# CC2753 register map
File version: 1.0
CPU: CM0+ r0p4, little endian, no MPU, no FPU, VTOR, 3 interrupt priority bits
Registers are 32-bit, read-write, reset 0x0 unless marked. A register's access mark holds for its fields unless they carry their own. Offsets are from the block's base; [hi:lo] are bit positions; 'fields as' and 'values as' point back to an identical list.

## CKMD (part 1 of 2) — Clock Controller
Base 0x40001000
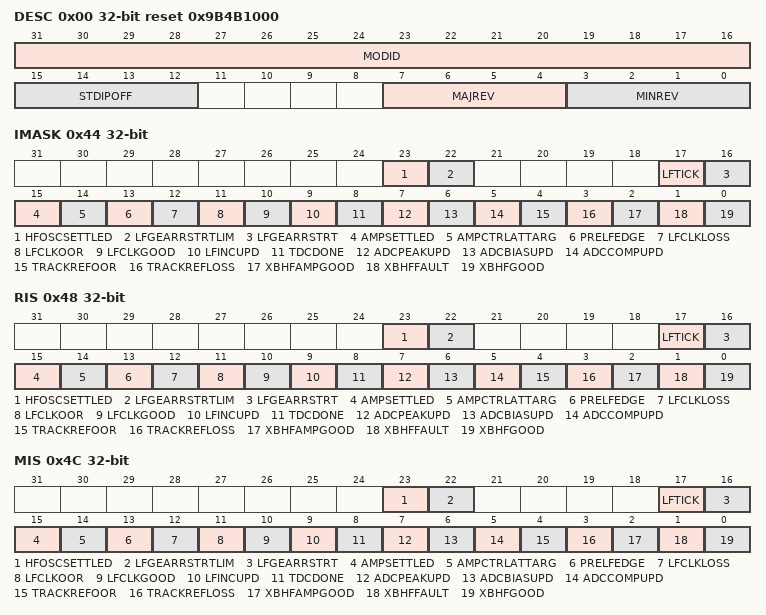
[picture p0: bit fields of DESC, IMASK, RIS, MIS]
0x00 DESC ro reset 0x9B4B1000 — Description Register. This register provides IP module ID, revision information, instance index and standard MMR registers offset.
  [31:16] MODID — Module identifier used to uniquely identify this IP.
  [15:12] STDIPOFF — Standard IP MMR block offset. Standard IP MMRs are the set of from aggregated IRQ registers till DTB. 0: Standard IP MMRs do not exist 0x1-0xF: Standard IP MMRs begin at offset of (64*STDIPOFF from the base IP address) NOTE: This IP does not have DTB as part of the Standard IP MMRs. It uses DTBCTL instead.
  [7:4] MAJREV — Major revision of IP (0-15).
  [3:0] MINREV — Minor revision of IP (0-15).
0x44 IMASK — Interrupt mask register
  [23] HFOSCSETTLED — Indicates that HFOSC has settled, based on LOOPCFG.SETTLED_TARGET and LOOPCFG1.SETTLEIRQ
  [22] LFGEARRSTRTLIM — Indicates that the LFINC filter gearing mechanism has restarted more than LFINCCTL2.GEARRSTRTLIM
  [17] LFTICK — 32kHz TICK to RTC and WDT. Either derived from selected LFCLK or generated from CLKULL in absence of LFCLK.
  [16] LFGEARRSTRT — LFINC filter gearing restart. Indicates that the LFINC filter restarted gearing. Subsequent LFINC estimates may have higher variation.
  [15] AMPSETTLED — HFXT Amplitude compensation - settled Indicates that the amplitude compensation FSM has reached the SETTLED or TCXOMODE state, and the controls configured in HFXTTARG or HFXTDYN are reached.
  [14] AMPCTRLATTARG — HFXT Amplitude compensation - controls at target Indicates that the control values configured in HFXTTARG or HFXTDYN are reached. Applies to Q1CAP, Q2CAP and IREF.
  [13] PRELFEDGE — Pre-LF clock edge detect. Indicates that a positive edge occured on the selected pre-LF clock CLKSEL.PRELFCLK' Can be used by software to confirm that a LF clock source is running and within the expected frequency, before selecting it as the main LF clock source.
  [12] LFCLKLOSS — LF clock is lost. Indicates that no LF clock edge occured for ~49us (~1.6 times nominal period). The system will automatically fall-back to generating LFTICK based on CLKULL, to avoid timing corruption. Note that this signal is NOT related to the analog LF clock-loss detector which can reset the device during STANDBY.
  [11] LFCLKOOR — LF clock period out-of-range. Indicates that a LF clock period was measured to be out-of-range, according to LFQUALCTL.MAXERR.
  [10] LFCLKGOOD — LF clock good. Indicates that the LF clock is good, according to the configuration in LFQUALCTL.
  [9] LFINCUPD — LFINC updated. Indicates that a new LFINC measurement value is available in CKM.LFCLKSTAT.
  [8] TDCDONE — TDC done event. Indicates that the TDC measurement is done.
  [7] ADCPEAKUPD — HFXT-ADC PEAK measurement update event. Indicates that the HFXT-ADC PEAK measurement is done.
  [6] ADCBIASUPD — HFXT-ADC BIAS measurement update event. Indicates that the HFXT-ADC BIAS measurement is done.
  [5] ADCCOMPUPD — HFXT-ADC comparison update event. Indicates that the HFXT-ADC comparison is done.
  [4] TRACKREFOOR — Out-of-range indication from the tracking loop. Indicates that the selected reference clock frequency of the tracking loop is out-of-range.
  [3] TRACKREFLOSS — Clock loss indication from the tracking loop. Indicates that the selected reference clock of the tracking loop is lost.
  [2] XBHFAMPGOOD — For HFXT it indicates that the amplitude is good. For BAW it indicates that the 1st stage qualification is done.
  [1] XBHFFAULT — HFXT/BAW fault indication. Indicates that HFXT/BAW did not start correctly, or its frequency is too low. HFXT/BAW will not recover from this fault and has to be restarted. This is only a one-time check at HFXT/BAW startup.
  [0] XBHFGOOD — HFXT/BAW good indication. Indicates that HFXT/BAW started correctly. The frequency is not necessarily good enough for radio operation. This is only a one-time check at HFXT/BAW startup.
0x48 RIS ro — Raw interrupt flag register
  [23] HFOSCSETTLED — Indicates that HFOSC has settled, based on LOOPCFG.SETTLED_TARGET and LOOPCFG1.SETTLEIRQ
  [22] LFGEARRSTRTLIM — Indicates that the LFINC filter gearing mechanism has restarted more than LFINCCTL2.GEARRSTRTLIM
  [17] LFTICK — 32kHz TICK to RTC and WDT. Either derived from selected LFCLK or generated from CLKULL in absence of LFCLK.
  [16] LFGEARRSTRT — LFINC filter gearing restart. Indicates that the LFINC filter restarted gearing. Subsequent LFINC estimates may have higher variation.
  [15] AMPSETTLED — HFXT Amplitude compensation - settled Indicates that the amplitude compensation FSM has reached the SETTLED or TCXOMODE state, and the controls configured in HFXTTARG or HFXTDYN are reached.
  [14] AMPCTRLATTARG — HFXT Amplitude compensation - controls at target Indicates that the control values configured in HFXTTARG or HFXTDYN are reached. Applies to Q1CAP, Q2CAP and IREF.
  [13] PRELFEDGE — Pre-LF clock edge detect. Indicates that a positive edge occured on the selected pre-LF clock CLKSEL.PRELFCLK' Can be used by software to confirm that a LF clock source is running and within the expected frequency, before selecting it as the main LF clock source.
  [12] LFCLKLOSS — LF clock is lost. Indicates that no LF clock edge occured for ~49us (~1.6 times nominal period). The system will automatically fall-back to generating LFTICK based on CLKULL, to avoid timing corruption. Note that this signal is NOT related to the analog LF clock-loss detector which can reset the device during STANDBY.
  [11] LFCLKOOR — LF clock period out-of-range. Indicates that a LF clock period was measured to be out-of-range, according to LFQUALCTL.MAXERR.
  [10] LFCLKGOOD — LF clock good. Indicates that the LF clock is good, according to the configuration in LFQUALCTL.
  [9] LFINCUPD — LFINC updated. Indicates that a new LFINC measurement value is available in CKM.LFCLKSTAT.
  [8] TDCDONE — TDC done event. Indicates that the TDC measurement is done.
  [7] ADCPEAKUPD — HFXT-ADC PEAK measurement update event. Indicates that the HFXT-ADC PEAK measurement is done.
  [6] ADCBIASUPD — HFXT-ADC BIAS measurement update event. Indicates that the HFXT-ADC BIAS measurement is done.
  [5] ADCCOMPUPD — HFXT-ADC comparison update event. Indicates that the HFXT-ADC comparison is done.
  [4] TRACKREFOOR — Out-of-range indication from the tracking loop. Indicates that the selected reference clock frequency of the tracking loop is out-of-range. Configured using the MMR LOOPCFG.OOR_LIMIT
  [3] TRACKREFLOSS — Clock loss indication from the tracking loop. Indicates that the selected reference clock of the tracking loop is lost.
  [2] XBHFAMPGOOD — For HFXT it indicates that the amplitude is good. For BAW it indicates that the 1st stage qualification is done.
  [1] XBHFFAULT — HFXT/BAW fault indication. Indicates that HFXT/BAW did not start correctly, or its frequency is too low. HFXT/BAW will not recover from this fault and has to be restarted. This is only a one-time check at HFXT/BAW startup.
  [0] XBHFGOOD — HFXT/BAW good indication. Indicates that HFXT/BAW started correctly. For HFXT, the frequency is not necessarily good enough for radio operation. For BAW, the frequency is good enough for radio operation. This is only a one-time check at HFXT/BAW startup.
0x4C MIS ro — Masked interrupt flag register
  [23] HFOSCSETTLED — Indicates that HFOSC has settled, based on LOOPCFG.SETTLED_TARGET and LOOPCFG1.SETTLEIRQ
  [22] LFGEARRSTRTLIM — Indicates that the LFINC filter gearing mechanism has restarted more than LFINCCTL2.GEARRSTRTLIM
  [17] LFTICK — 32kHz TICK to RTC and WDT. Either derived from selected LFCLK or generated from CLKULL in absence of LFCLK.
  [16] LFGEARRSTRT — LFINC filter gearing restart. Indicates that the LFINC filter restarted gearing. Subsequent LFINC estimates may have higher variation.
  [15] AMPSETTLED — HFXT Amplitude compensation - settled Indicates that the amplitude compensation FSM has reached the SETTLED or TCXOMODE state, and the controls configured in HFXTTARG or HFXTDYN are reached.
  [14] AMPCTRLATTARG — HFXT Amplitude compensation - controls at target Indicates that the control values configured in HFXTTARG or HFXTDYN are reached. Applies to Q1CAP, Q2CAP and IREF.
  [13] PRELFEDGE — Pre-LF clock edge detect. Indicates that a positive edge occured on the selected pre-LF clock CLKSEL.PRELFCLK' Can be used by software to confirm that a LF clock source is running and within the expected frequency, before selecting it as the main LF clock source.
  [12] LFCLKLOSS — LF clock is lost. Indicates that no LF clock edge occured for ~49us (~1.6 times nominal period). The system will automatically fall-back to generating LFTICK based on CLKULL, to avoid timing corruption. Note that this signal is NOT related to the analog LF clock-loss detector which can reset the device during STANDBY.
  [11] LFCLKOOR — LF clock period out-of-range. Indicates that a LF clock period was measured to be out-of-range, according to LFQUALCTL.MAXERR.
  [10] LFCLKGOOD — LF clock good. Indicates that the LF clock is good, according to the configuration in LFQUALCTL.
  [9] LFINCUPD — LFINC updated. Indicates that a new LFINC measurement value is available in CKM.LFCLKSTAT.
  [8] TDCDONE — TDC done event. Indicates that the TDC measurement is done.
  [7] ADCPEAKUPD — HFXT-ADC PEAK measurement update event. Indicates that the HFXT-ADC PEAK measurement is done.
  [6] ADCBIASUPD — HFXT-ADC BIAS measurement update event. Indicates that the HFXT-ADC BIAS measurement is done.
  [5] ADCCOMPUPD — HFXT-ADC comparison update event. Indicates that the HFXT-ADC comparison is done.
  [4] TRACKREFOOR — Out-of-range indication from the tracking loop. Indicates that the selected reference clock frequency of the tracking loop is out-of-range.
  [3] TRACKREFLOSS — Clock loss indication from the tracking loop. Indicates that the selected reference clock of the tracking loop is lost.
  [2] XBHFAMPGOOD — For HFXT it indicates that the amplitude is good. For BAW it indicates that the 1st stage qualification is done.
  [1] XBHFFAULT — HFXT/BAW fault indication. Indicates that HFXT/BAW did not start correctly, or its frequency is too low. HFXT/BAW will not recover from this fault and has to be restarted. This is only a one-time check at HFXT/BAW startup.
  [0] XBHFGOOD — HFXT/BAW good indication. Indicates that HFXT/BAW started correctly. For HFXT, the frequency is not necessarily good enough for radio operation. For BAW, the frequency is good enough for radio operation. This is only a one-time check at HFXT/BAW startup.
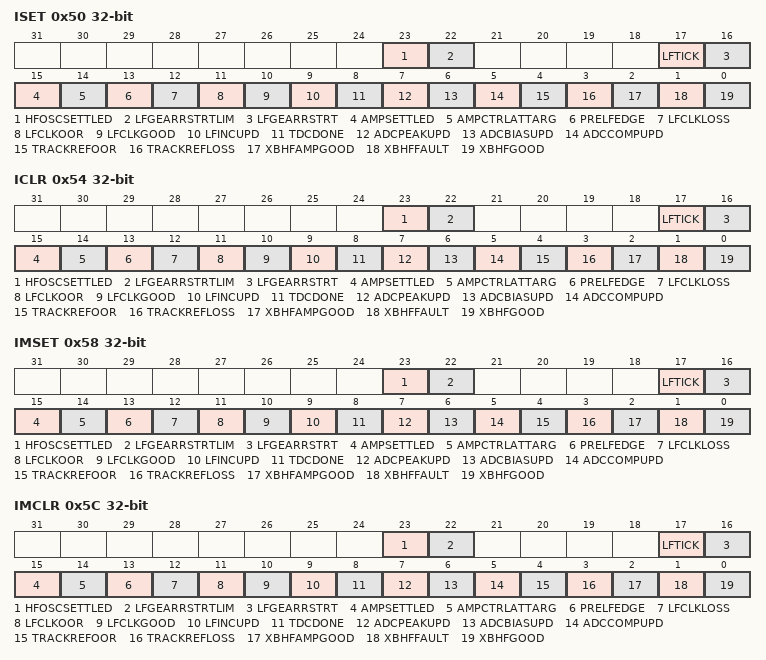
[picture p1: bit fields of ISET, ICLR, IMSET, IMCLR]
0x50 ISET wo — Interrupt flag set register
  fields as MIS
0x54 ICLR wo — Interrupt flag clear register
  fields as MIS
0x58 IMSET wo — Interrupt mask set register
  [23] HFOSCSETTLED — Indicates that HFOSC has settled, based on LOOPCFG.SETTLED_TARGET and LOOPCFG1.SETTLEIRQ
  [22] LFGEARRSTRTLIM — Indicates that the LFINC filter gearing mechanism has restarted more than LFINCCTL2.GEARRSTRTLIM
  [17] LFTICK — 32kHz TICK to RTC and WDT. Either derived from selected LFCLK or generated from CLKULL in absence of LFCLK.
  [16] LFGEARRSTRT — LFINC filter gearing restart. Indicates that the LFINC filter restarted gearing. Subsequent LFINC estimates may have higher variation.
  [15] AMPSETTLED — HFXT Amplitude compensation - settled Indicates that the amplitude compensation FSM has reached the SETTLED or TCXOMODE state, and the controls configured in HFXTTARG or HFXTDYN are reached.
  [14] AMPCTRLATTARG — HFXT Amplitude compensation - controls at target Indicates that the control values configured in HFXTTARG or HFXTDYN are reached. Applies to Q1CAP, Q2CAP and IREF.
  [13] PRELFEDGE — Pre-LF clock edge detect. Indicates that a positive edge occured on the selected pre-LF clock CLKSEL.PRELFCLK' Can be used by software to confirm that a LF clock source is running and within the expected frequency, before selecting it as the main LF clock source.
  [12] LFCLKLOSS — LF clock is lost. Indicates that no LF clock edge occured for ~49us (~1.6 times nominal period). The system will automatically fall-back to generating LFTICK based on CLKULL, to avoid timing corruption. Note that this signal is NOT related to the analog LF clock-loss detector which can reset the device during STANDBY.
  [11] LFCLKOOR — LF clock period out-of-range. Indicates that a LF clock period was measured to be out-of-range, according to LFQUALCTL.MAXERR.
  [10] LFCLKGOOD — LF clock good. Indicates that the LF clock is good, according to the configuration in LFQUALCTL.
  [9] LFINCUPD — LFINC updated. Indicates that a new LFINC measurement value is available in CKM.LFCLKSTAT.
  [8] TDCDONE — TDC done event. Indicates that the TDC measurement is done.
  [7] ADCPEAKUPD — HFXT-ADC PEAK measurement update event. Indicates that the HFXT-ADC PEAK measurement is done.
  [6] ADCBIASUPD — HFXT-ADC BIAS measurement update event. Indicates that the HFXT-ADC BIAS measurement is done.
  [5] ADCCOMPUPD — HFXT-ADC comparison update event. Indicates that the HFXT-ADC comparison is done.
  [4] TRACKREFOOR — Out-of-range indication from the tracking loop. Indicates that the selected reference clock frequency of the tracking loop is out-of-range.
  [3] TRACKREFLOSS — Clock loss indication from the tracking loop. Indicates that the selected reference clock of the tracking loop is lost.
  [2] XBHFAMPGOOD — HFXT amplitude good indication.
  [1] XBHFFAULT — HFXT/BAW fault indication. Indicates that HFXT/BAW did not start correctly, or its frequency is too low. HFXT/BAW will not recover from this fault and has to be restarted. This is only a one-time check at HFXT/BAW startup.
  [0] XBHFGOOD — HFXT/BAW good indication. Indicates that HFXT/BAW started correctly. For HFXT, the frequency is not necessarily good enough for radio operation. For BAW, the frequency is good enough for radio operation. This is only a one-time check at HFXT/BAW startup.
0x5C IMCLR wo — Indicates that HFOSC has settled, based on LOOPCFG.SETTLED_TARGET
  fields as MIS
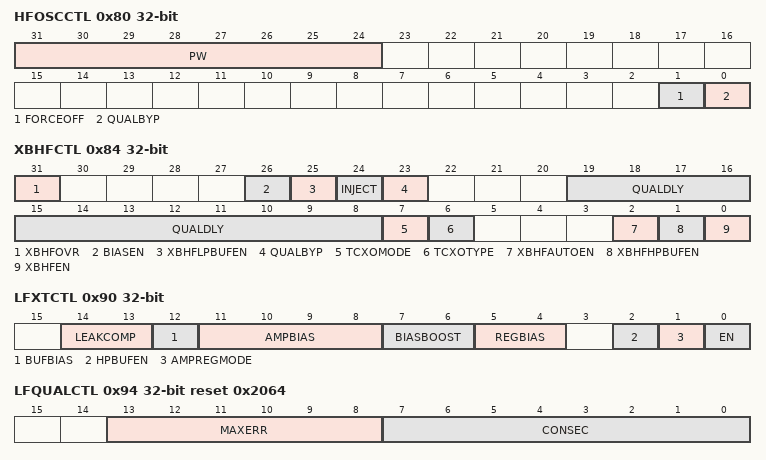
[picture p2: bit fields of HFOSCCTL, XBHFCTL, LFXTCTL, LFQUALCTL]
0x80 HFOSCCTL — High frequency oscillator control
  [31:24] PW wo — Password protection for QUALBYP and FORCEOFF. Write this field to 0xA5 to accept writes to QUALBYP and FORCEOFF.
  [1] FORCEOFF — Force HFOSC off. Once this MMR is set, the system will stop. The only way to start the system again is system reset. This field is locked using the global-lock within SYS0.
  [0] QUALBYP — Clock qualification bypass. HFOSC qualification will skip a fixed number of clock cycles to prevent glitches or frequency overshoots from reaching the system. Setting this bit will bypass the qualification. This bit can be locked in SYS0. If unlocked, it is password protected with PW.
0x84 XBHFCTL — High frequency crystal controls
  [31] XBHFOVR — Software override for the HFXT amplitude compensation FSM or BAW control FSM HFXT overrides :- Directly use control values in CKM.HFXTDYN0 and CKM.HFXTDYN1. Control injection and clock buffer using INJECT and LPBUFEN. BAW overrides :- Directly use control values in CKM.BAWCTL
  [26] BIASEN — HFXT bias enable. Controls the biasing if XBHFOVR is set. Otherwise, the biasing is controlled by the amplitude compensation FSM.
  [25] XBHFLPBUFEN — Low power clock buffer enable. Controls the clock buffer if XBHFOVR is set. Otherwise, the buffer is controlled by the amplitude compensation FSM in case of HFXT or BAW control FSM in case of BAW.
  [24] INJECT — Control HFXT injection if XBHFOVR is set.
  [23] QUALBYP — Bypass HFXT clock qualification. Enables HFXT propagation to the system without waiting for the qualification circuit. NOTE: To actually bypass the qualification, program QUALDLY to 0 along with setting QUALBYP to 0
  [19:8] QUALDLY — Skip potentially unstable clock cycles after enabling HFXT. Number of cycles skipped is 8*QUALDLY.
  [7] TCXOMODE — Temperature compensated crystal oscillator mode. Set this bit if a TXCO is connected.
  [6] TCXOTYPE — Type of temperature compensated crystal used. Only has effect if TCXOMODE is set.
    1=CMOS; 0=CLIPPEDSINE
  [2] XBHFAUTOEN — Automatic enable. If this bit is set, EN will automatically be set at wakeup or before (using pre-wake mechanism in RTC).
  [1] XBHFHPBUFEN — High performance clock buffer enable. This bit controls the clock output for the RF PLL. It is required for radio operation.
  [0] XBHFEN — HFXT/BAW enable. Setting this bit will enable HFXT/BAW. REFOSCSEL.XBHF selects which circuit get's enabled. It will automatically be cleared upon STANDBY entry. If XBHFAUTOEN is set, this bit will be set automatically on wakeup or before (pre-wake mechanism in RTC).
0x8C LFOSCCTL — Low frequency oscillator control
  [0] EN — LFOSC enable
0x90 LFXTCTL — Low frequency crystal control
  [14:13] LEAKCOMP — Leakage compensation control
    3=OFF (No leakage compensation); 1=HALF (Half leakage compensation); 0=FULL (Full leakage compensation)
  [12] BUFBIAS — Control the BIAS current of the input amp in LP buffer
    1=MAX (Maximum bias current: 50nA); 0=MIN (Minimum bias current: 25nA)
  [11:8] AMPBIAS — Adjust current mirror ratio into oscillator core. This value is depending on crystal and is set by FW. This field uses a 2's complement encoding.
  [7:6] BIASBOOST — Boost oscillator amplitude This value depends on the crystal and needs to be configured by Firmware.
  [5:4] REGBIAS — Regulation loop bias resistor value This value depends on the crystal and needs to be configured by Firmware.
  [2] HPBUFEN — Control the buffer used. In normal operation, low-power buffer is used in all device modes. The high-performance buffer is only used for test purposes.
  [1] AMPREGMODE — Amplitude regulation mode
    1=LOOPDIS (Amplitude control loop disabled); 0=LOOPEN (Amplitude control loop enabled)
  [0] EN — LFXT enable
0x94 LFQUALCTL reset 0x2064 — Low frequency clock qualification control
  [13:8] MAXERR — Maximum LFCLK period error. Value given in microseconds, 3 integer bits + 3 fractional bits.
  [7:0] CONSEC — Number of consecutive times the LFCLK period error has to be smaller than MAXERR to be considered "good". Setting this value to 0 will bypass clock qualification, and the "good" indicator will always be 1.
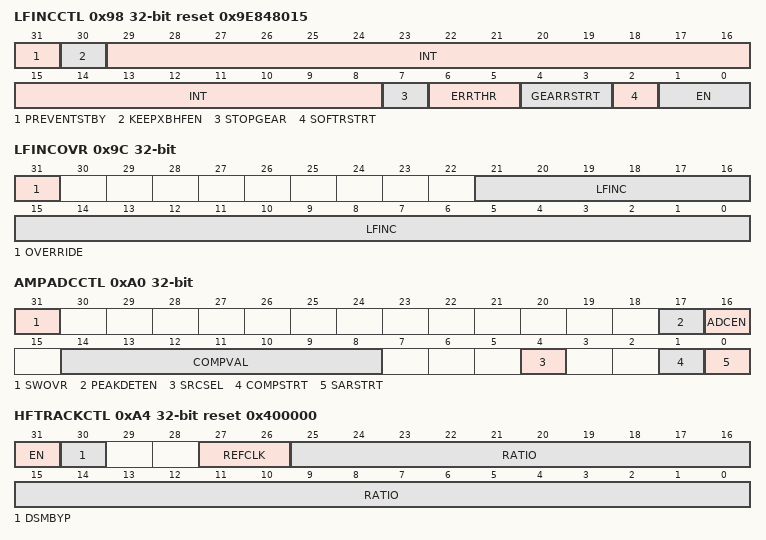
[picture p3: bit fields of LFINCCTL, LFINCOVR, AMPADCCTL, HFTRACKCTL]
0x98 LFINCCTL reset 0x9E848015 — Low frequency time increment control
  [31] PREVENTSTBY — Controls if the LFINC filter prevents STANBY entry until settled. Note :- Writing to PREVENTSTBY when LFINC filter is running will interfere with the filter operation as INT bitfield is the filter accumulator which is updated by hardware. The best practice is to configure PREVENTSTBY before HFOSC tracking loop and LFOSC is enabled. But still if it is needed to configure this bitfield when the LFINC filter is running, the following software sequence should be followed :- 1. Clear RIS.LFTICK and set IMASK.LFTICK 2. Wait for an interrupt in RIS.LFTICK 3. Read LFINCCTL 4. Modify LFINCCTL to update only PREVENTSTBY bitfield and write back
    1=ON (Enable. Prevent STANDBY entry.); 0=OFF (Disable. Do not prevent STANDBY entry.)
  [30] KEEPXBHFEN — Keeps the HFXT/BAW enabled till the LFINC filter settles. Note :- Writing to KEEPXBHFEN when LFINC filter is running will interfere with the filter operation as INT bitfield is the filter accumulator which is updated by hardware. The best practice is to configure KEEPXBHFEN before HFOSC tracking loop and LFOSC is enabled. But still if it is needed to configure this bitfield when the LFINC filter is running, the following software sequence should be followed :- 1. Clear RIS.LFTICK and set IMASK.LFTICK 2. Wait for an interrupt in RIS.LFTICK 3. Read LFINCCTL 4. Modify LFINCCTL to update only KEEPXBHFEN bitfield and write back
    1=EN (Enable. Keep HFXT/BAW enabled.); 0=DIS (Disable. Do not keep HFXT/BAW enabled.)
  [29:8] INT — Integral part of the LFINC filter. This value is updated by Hardware to reflect the current state of the filter. It can also be written to change the current state.
  [7] STOPGEAR — Controls the final gear of the LFINC filter.
    1=HIGH (The LF filter is considered settled when LFCLKSTAT2.MAINGEAR reads 8 and LFCLKSTAT2.SUBGEAR reads 7. That means the LF filter will take 71 LF periods to settle, when the gears start from 0 and also assuming the gear does not restarts.); 0=LOW (The LF filter is considered settled when LFCLKSTAT2.MAINGEAR reads 9 and LFCLKSTAT2.SUBGEAR reads 7. That means the LF filter will take 79 LF periods to settle, when the gears start from 0 and also assuming the gear does not restarts.)
  [6:5] ERRTHR — Controls the threshold for gearing restart of the LFINC filter. Only effective if GEARRSTRT is not ONETHR or TWOTHR.
    3=SMALL (Restart gearing on small error. Potentially more false restarts, faster response on small frequency shifts.); 2=MIDSMALL (Middle value towards SMALL.); 1=MIDLARGE (Middle value towards LARGE.); 0=LARGE (Restart gearing on large error. Fewer false restarts, slower response on small frequency shifts.)
  [4:3] GEARRSTRT — Controls gearing restart of the LFINC filter.
    2=TWOTHR (Restart gearing when the error accumulator crosses the threshold twice in a row.); 1=ONETHR (Restart gearing when the error accumulator crosses the threshold once.); 0=NEVER (Never restart gearing. Very stable filter value, but very slow response on frequency changes.)
  [2] SOFTRSTRT — Use a lower gear after re-enabling / wakeup. The filter will require 16-24 LFCLK periods to settle (depending on STOPGEAR), but may respond faster to frequency changes during STANDBY.
    1=ON (Use soft gearing restarts); 0=OFF (Don't use soft gearing restarts)
  [1:0] EN — Enable LFINC filter. Programming with a value of 0x3 will disable the LFINC filter
    2=AUTO (Enable based on HFOS getting settled. HFOSC gets settled after the tracking loop has updated equal to or more than LOOPCFG.SETTLED_TARGET times. This option is effective only if the system is running on HFXT instead of BAW); 1=EN (ENABLED); 0=DIS (DISABLED)
0x9C LFINCOVR — Low frequency time increment override control
  [31] OVERRIDE — Override LF increment Use the value provided in LFINC instead of the value calculated by Hardware.
  [21:0] LFINC — LF increment value This value is used when OVERRIDE is set to 1. Otherwise the value is calculated automatically. The current LFINC value can be read from [CKM.LFCLKSTAT.LFINC].
0xA0 AMPADCCTL — Amplitude ADC control
  [31] SWOVR — Software override. Control Amplitude ADC from software. Directly use control values in SARSTRT, COMPSTRT, SRCSEL, COMPVAL, ADCEN and PEAKDETEN.
  [17] PEAKDETEN — Enable HFXT Peak Detector. If the peak detector is used by the AMPCOMP FSM, this bit can be used to keep the peak detector always enabled. If SWOVR is set, this bit directly controls the peak detector.
    1=ENABLE (Enable peak detector); 0=DISABLE (Disable peak detector (unless requested by AMPCOMP FSM))
  [16] ADCEN — Enable Amplitude ADC. If the ADC is used by the AMPCOMP FSM, this bit can be used to keep the ADC always enabled. If SWOVR is set, this bit directly controls the ADC.
    1=ENABLE (Enable ADC); 0=DISABLE (Disable ADC (unless requested by AMPCOMP FSM))
  [14:8] COMPVAL — Comparator reference input in compare mode This bitfield is only active if SWOVR is set. SRCSEL selects the source to be compared. Result will be available in CKM.AMPADCSTAT.
  [4] SRCSEL — Select the input to the ADC Only active if SWOVR is set.
    1=PEAK (Measure HFXT peak voltage); 0=BIAS (Measure bias voltage)
  [1] COMPSTRT — Start a comparison This bit is only active if SWOVR is set. SRCSEL selects the source to be measured. COMPVAL configures the threshold value. Result will be available in CKM.AMPADCSTAT.
  [0] SARSTRT — Start a SAR conversion This bit is only active if SWOVR is set. SRCSEL selects the source to be measured. Result will be available in CKM.AMPADCSTAT.
0xA4 HFTRACKCTL reset 0x400000 — High frequency tracking loop control
  [31] EN — Enable tracking loop.
  [30] DSMBYP — Bypass Delta-Sigma-Modulation of fine trim.
  [27:26] REFCLK — Select the reference clock for the tracking loop. Change only while the tracking loop is disabled.
    3=NONE (No reference clock running); 2=GPI (Select GPI as reference clock.); 1=LRF (Select LRF reference clock.); 0=XBHF (Select XBHF/BAW as reference clock.)
  [25:0] RATIO — Ratio. Ratio format is 2b.24b
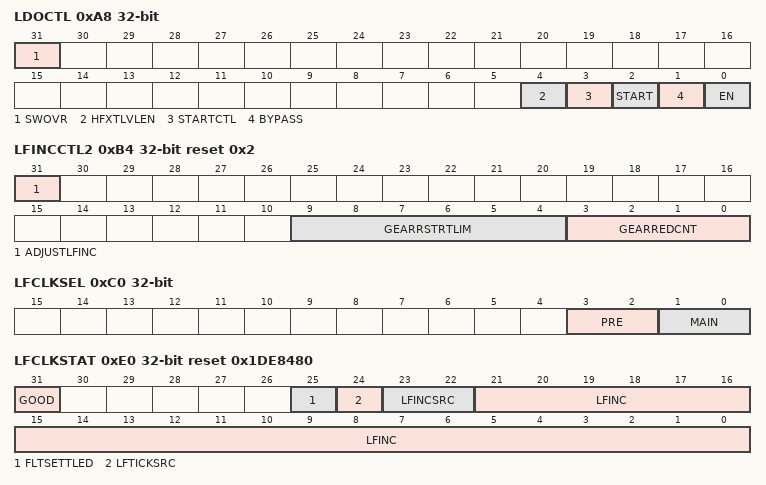
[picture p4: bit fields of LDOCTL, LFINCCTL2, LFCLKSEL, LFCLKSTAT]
0xA8 LDOCTL — LDO control By default, the LDO is controlled by the HFXT Amplitude compensation. This register is used for software overrides.
  [31] SWOVR — Software override. Control LDO from software. Directly use control values in EN, BYPASS, START, STARTCTL and HFXTLVLEN.
  [4] HFXTLVLEN — Enable levelshifters from ULL to VCKM. Needs to be timer-based. Worst-case LDO startup time is 5us across PVT. Use this value if SWOVR is set.
  [3] STARTCTL — Enable faster startup. Use this value if SWOVR is set. This bit should be set together with EN, and cleared after 5us.
  [2] START — Enable faster startup. Use this value if SWOVR is set. This bit should be set together with EN, and cleared after 5us.
  [1] BYPASS — Bypass LDO. Use this value if SWOVR is set.
  [0] EN — Enable LDO. Use this value if SWOVR is set.
0xAC NABIASCTL — Nanoamp-bias control
  [0] EN — Enable nanoamp-bias
0xB0 LFMONCTL — Low-frequency clock-monitor control
  [0] EN — Enable LFMONITOR. Enable only after a LF clock source has been selected, enabled and is stable. If LFMONITOR detects a clock loss, the system will be reset.
0xB4 LFINCCTL2 reset 0x2 — Low frequency time increment control-2
  [31] ADJUSTLFINC — Adjusts LFINC while transitioning from fake to real LF clock if necessary. For the adjustment to happen, tracking loop must be running.
  [9:4] GEARRSTRTLIM — Specifies the number of times gear could be restarted before raising an interrupt. It has no impact on the number of times gear can be reduced. A value of 0 indicates that the interrupt mechanism is disabled
  [3:0] GEARREDCNT — Specifies the number by which gear should be reduced post standby exit
0xC0 LFCLKSEL — Low frequency clock selection
  [3:2] PRE — Select low frequency clock source for the PRELFCLK interrupt. Can be used by Software to confirm that the clock is running and it's frequency is good, before selecting it in MAIN.
    3=EXTLF (External LF clock through GPI.); 1=LFOSC (Low frequency on-chip oscillator); 0=NONE (No clock. Output will be tied low.)
  [1:0] MAIN — Select the main low frequency clock source. If running, this clock will be used to generate LFTICK and as CLKULL during STANDBY. If not running, LFTICK will be generated from HFOSC and STANDBY entry will be prevented.
    3=EXTLF (External LF clock through GPI.); 1=LFOSC (Low frequency on-chip oscillator); 0=FAKE (No LF clock selected. LFTICK will be generated from HFOSC, STANDBY entry will be prevented.)
0xC4 TDCCLKSEL — TDC clock selection
  [2:0] REFCLK — Select reference clock for the TDC.
    5=XBHF (48MHz BAW or HFXT clock); 3=GPI (General purpose input signal); 2=CLKULL (24MHz CLKULL); 1=CLKSVT (96MHz HFOSC clock div by 2); 0=NONE (No reference clock)
0xC8 ADCCLKSEL — ADC clock selection
  [1:0] SRC — Select ADC clock source Change only while ADC is disabled!
    1=HFXT (48MHz HFXT); 0=CLKSVT (48MHz CLKSVT)
0xE0 LFCLKSTAT ro reset 0x1DE8480 — Low-frequency clock status
  [31] GOOD — Low frequency clock good Note: This is only a coarse frequency check based on LFQUALCTL. The clock may not be accurate enough for timing purposes.
  [25] FLTSETTLED — LFINC filter is running and settled.
  [24] LFTICKSRC — Source of LFTICK.
    1=FAKE (LFTICK generated from CLKULL (LFCLK not available)); 0=LFCLK (LFTICK generated from the selected LFCLK)
  [23:22] LFINCSRC — Source of LFINC used by the RTC. This value depends on LFINCOVR.OVERRIDE, LFINCCTL.EN and the device state (ACTIVE/STANDBY).
    3=FAKE (Using FAKE LFTICKs with corresponding LFINC value.); 2=OVERRIDE (Using override value from LFINCOVR.LFINC); 1=AVG (Using filtered / average value. This value is updated by hardware and can be read and updated in LFINCCTL.INT.); 0=MEAS (Using measured value. This value is updated by hardware and can be read from LFINC.)
  [21:0] LFINC — Measured value of LFINC. Given in microseconds with 16 fractional bits. This value is calculated by Hardware. It is the LFCLK period according to CLKULL cycles.
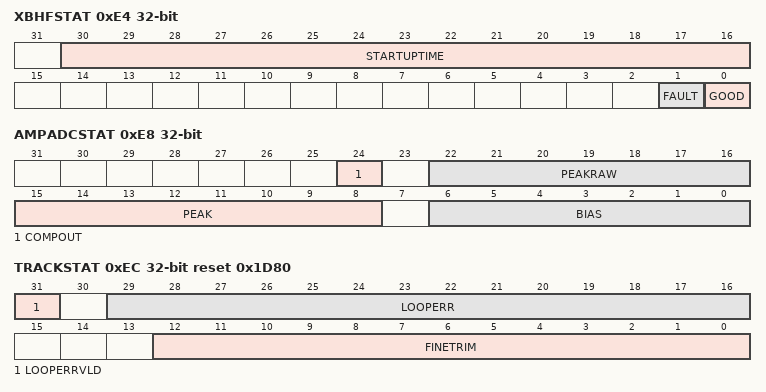
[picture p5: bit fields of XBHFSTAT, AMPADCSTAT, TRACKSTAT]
0xE4 XBHFSTAT ro — HFXT/BAW status information
  [30:16] STARTUPTIME — HFXT startup time Can be used by software to plan starting HFXT ahead in time. Measured whenever HFXT is enabled in CLKULL periods (24MHz), from [CKM.HFXTCTL.EN] until the clock is good for radio operation (amplitude compensation is settled).
  [1] FAULT — HFXT clock fault Indicates a lower than expected HFXT frequency. HFXT will not recover from this fault, disabling and re-enabling HFXT is required.
  [0] GOOD — HFXT clock available
0xE8 AMPADCSTAT ro — HFXT Amplitude ADC Status
  [24] COMPOUT — Most recent comparison output
  [22:16] PEAKRAW — Most recently measured peak voltage - raw This value is the raw output of the HFXT ADC. For the actual peak voltage use the value (PEAK + 0.0150)/0.74 + K, where 'K' is a function of process variation and is stored in FCFG1 register.
  [15:8] PEAK — Most recently measured peak voltage - bias corrected This value is computed as 2*PEAKRAW-BIAS Actual voltage = (2*PEAKRAW-BIAS - 0.015)/0.74 + K, where 'K' is a function of process variation and is stored in FCFG1 register.
  [6:0] BIAS — Most recently measured bias voltage
0xEC TRACKSTAT reset 0x1D80 — HF tracking loop status information
  [31] LOOPERRVLD ro — Current HFOSC tracking error valid This bit is one if the tracking loop is running and the error value is valid.
  [29:16] LOOPERR ro — Current HFOSC tracking error This field uses the internal fractional representation (sign, 9 integer bits, 4 fractional bits).
  [12:0] FINETRIM ro — Current HFOSC Fine-trim value This field uses the internal fractional representation (sign, 5 integer bits, 7 fractional bits). The actual trim value applied to the oscillator is delta-sigma modulated 6 bits non-signed (inverted sign bit + integer bits). INTERNAL This field can be written by also writing a magic value (0xA5) into LOOPERR (bits 23:16)
